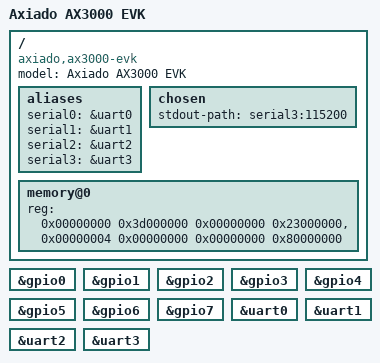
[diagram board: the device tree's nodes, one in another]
// SPDX-License-Identifier: GPL-2.0+
/*
 * Copyright (c) 2021-25 Axiado Corporation (or its affiliates). All rights reserved.
 */

/dts-v1/;

#include "ax3000.dtsi"

/ {
	model = "Axiado AX3000 EVK";
	compatible = "axiado,ax3000-evk", "axiado,ax3000";
	#address-cells = <2>;
	#size-cells = <2>;

	aliases {
		serial0 = &uart0;
		serial1 = &uart1;
		serial2 = &uart2;
		serial3 = &uart3;
	};

	chosen {
		stdout-path = "serial3:115200";
	};

	memory@0 {
		device_type = "memory";
		/* Cortex-A53 will use following memory map */
		reg = <0x00000000 0x3d000000 0x00000000 0x23000000>,
		      <0x00000004 0x00000000 0x00000000 0x80000000>;
	};
};

/* GPIO bank 0 - 7 */
&gpio0 {
	status = "okay";
};

&gpio1 {
	status = "okay";
};

&gpio2 {
	status = "okay";
};

&gpio3 {
	status = "okay";
};

&gpio4 {
	status = "okay";
};

&gpio5 {
	status = "okay";
};

&gpio6 {
	status = "okay";
};

&gpio7 {
	status = "okay";
};

&uart0 {
	status = "okay";
};

&uart1 {
	status = "okay";
};

&uart2 {
	status = "okay";
};

&uart3 {
	status = "okay";
};
